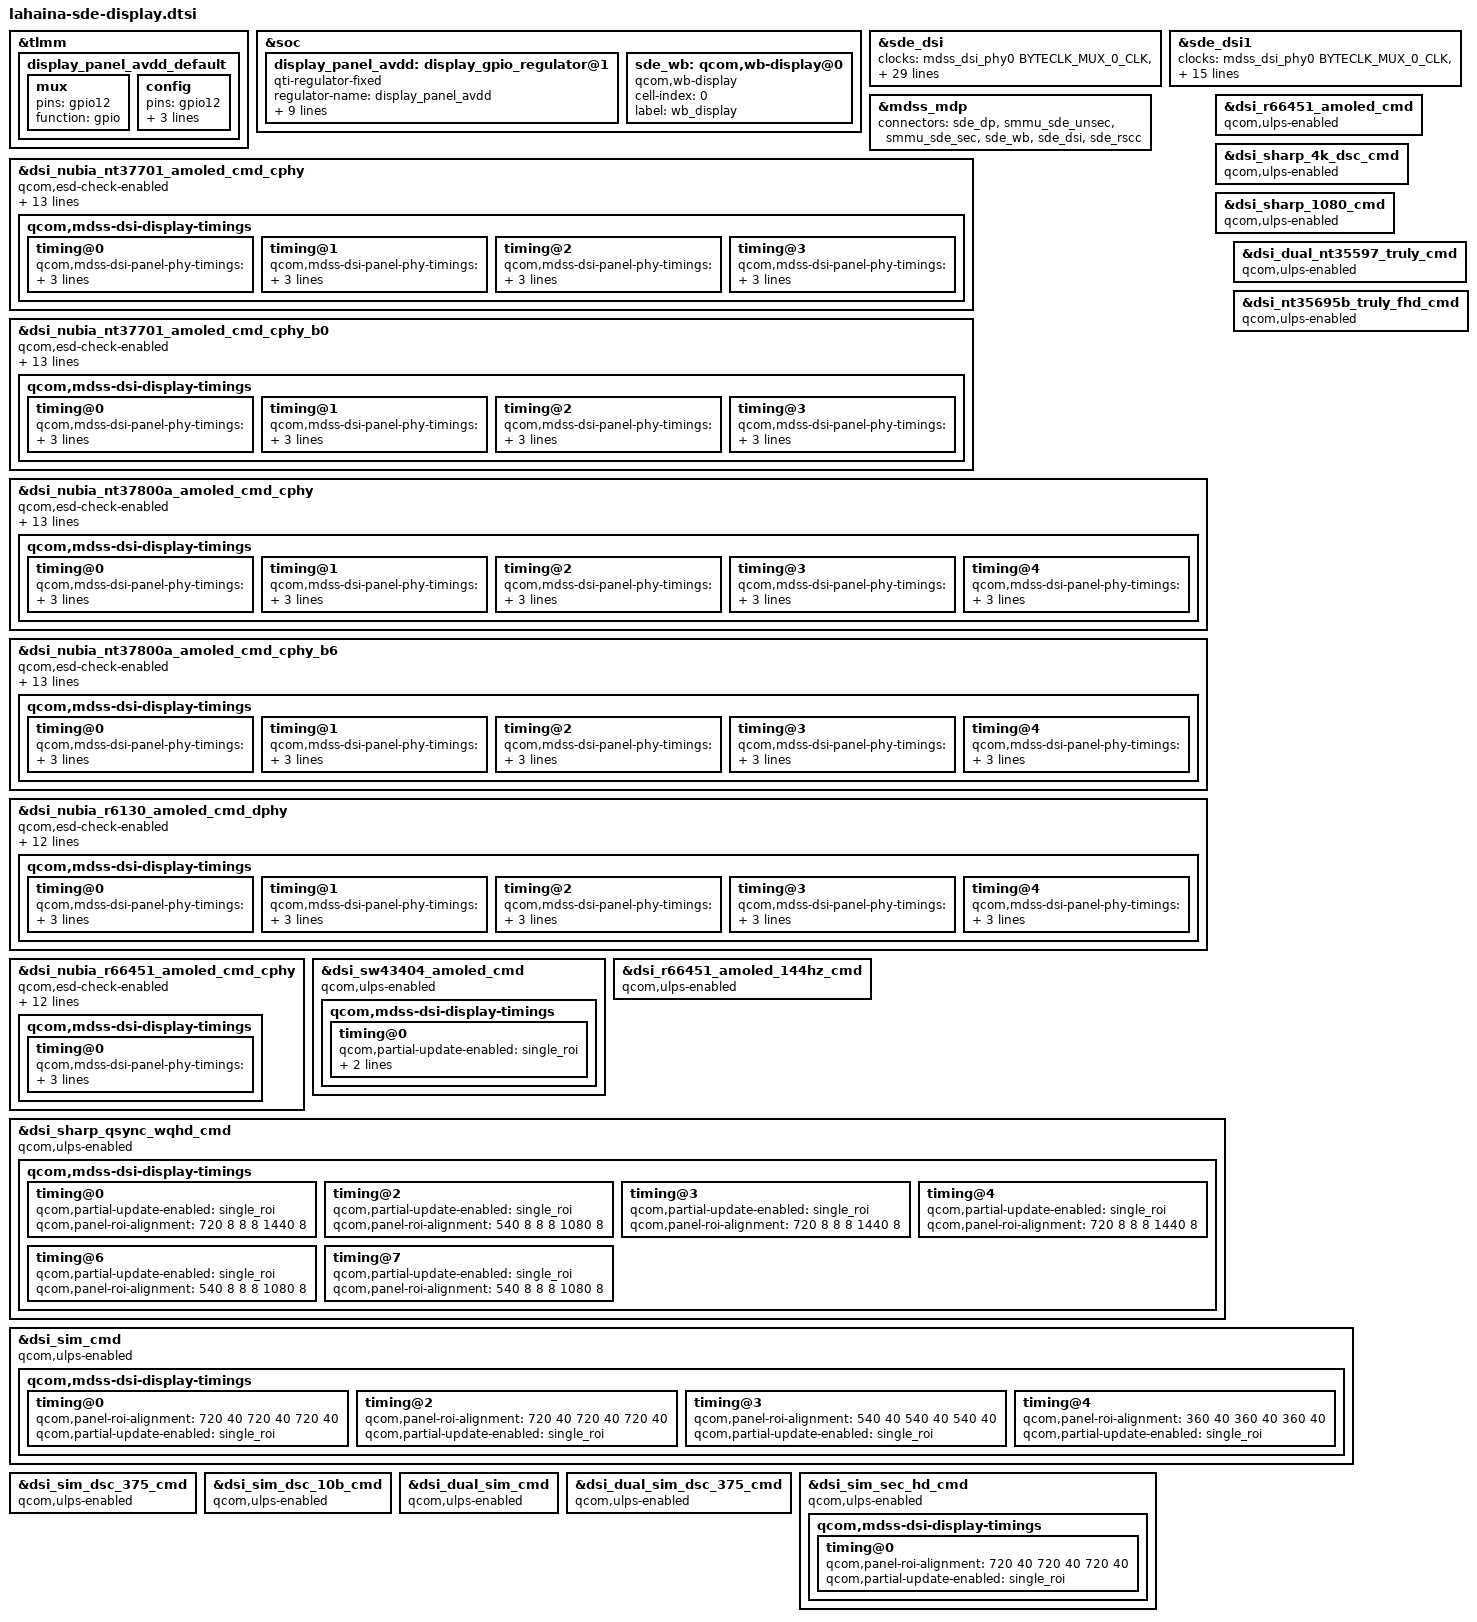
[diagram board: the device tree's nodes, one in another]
#include "lahaina-sde-display-common.dtsi"
#include <dt-bindings/clock/qcom,dispcc-lahaina.h>

&tlmm {
	display_panel_avdd_default: display_panel_avdd_default {
		mux {
			pins = "gpio12";
			function = "gpio";
		};

		config {
			pins = "gpio12";
			drive-strength = <8>;
			bias-disable = <0>;
			output-high;
		};
	};
};

&soc {
	display_panel_avdd: display_gpio_regulator@1 {
		compatible = "qti-regulator-fixed";
		regulator-name = "display_panel_avdd";
		regulator-min-microvolt = <5500000>;
		regulator-max-microvolt = <5500000>;
		regulator-enable-ramp-delay = <233>;
		gpio = <&tlmm 12 0>;
		enable-active-high;
		regulator-boot-on;
		proxy-supply = <&display_panel_avdd>;
		qcom,proxy-consumer-enable;
		pinctrl-names = "default";
		pinctrl-0 = <&display_panel_avdd_default>;
	};

	sde_wb: qcom,wb-display@0 {
		compatible = "qcom,wb-display";
		cell-index = <0>;
		label = "wb_display";
	};
};

&sde_dsi {
	clocks = <&mdss_dsi_phy0 BYTECLK_MUX_0_CLK>,
			 <&mdss_dsi_phy0 PCLK_MUX_0_CLK>,
			 <&mdss_dsi_phy0 CPHY_BYTECLK_SRC_0_CLK>,
			 <&mdss_dsi_phy0 CPHY_PCLK_SRC_0_CLK>,
			 <&mdss_dsi_phy0 BYTECLK_SRC_0_CLK>,
			 <&mdss_dsi_phy0 PCLK_SRC_0_CLK>,
			 <&mdss_dsi_phy0 SHADOW_BYTECLK_SRC_0_CLK>,
			 <&mdss_dsi_phy0 SHADOW_PCLK_SRC_0_CLK>,
			 <&mdss_dsi_phy0 SHADOW_CPHY_BYTECLK_SRC_0_CLK>,
			 <&mdss_dsi_phy0 SHADOW_CPHY_PCLK_SRC_0_CLK>,
			 <&mdss_dsi_phy1 BYTECLK_MUX_1_CLK>,
			 <&mdss_dsi_phy1 PCLK_MUX_1_CLK>,
			 <&mdss_dsi_phy1 CPHY_BYTECLK_SRC_1_CLK>,
			 <&mdss_dsi_phy1 CPHY_PCLK_SRC_1_CLK>,
			 <&mdss_dsi_phy1 BYTECLK_SRC_1_CLK>,
			 <&mdss_dsi_phy1 PCLK_SRC_1_CLK>,
			 <&mdss_dsi_phy1 SHADOW_BYTECLK_SRC_1_CLK>,
			 <&mdss_dsi_phy1 SHADOW_PCLK_SRC_1_CLK>,
			 <&mdss_dsi_phy1 SHADOW_CPHY_BYTECLK_SRC_1_CLK>,
			 <&mdss_dsi_phy1 SHADOW_CPHY_PCLK_SRC_1_CLK>,
			 /*
			  * Currently the dsi clock handles are under the dsi
			  * controller DT node. As soon as the controller probe
			  * finishes, the dispcc sync state can get called before
			  * the dsi_display probe potentially disturbing the clock
			  * votes for cont_splash use case. Hence we are no longer
			  * protected by the component model in this case against the
			  * disp cc sync state getting triggered after the dsi_ctrl
			  * probe. To protect against this incorrect sync state trigger
			  * add this dummy MDP clk vote handle to the dsi_display
			  * DT node. Since the dsi_display driver does not parse
			  * MDP clock nodes, no actual vote shall be added and this
			  * change is done just to satisfy sync state requirements.
			  */
			 <&clock_dispcc DISP_CC_MDSS_MDP_CLK>;
	clock-names = "mux_byte_clk0", "mux_pixel_clk0",
			"cphy_byte_clk0", "cphy_pixel_clk0",
			"src_byte_clk0", "src_pixel_clk0",
			"shadow_byte_clk0", "shadow_pixel_clk0",
			"shadow_cphybyte_clk0", "shadow_cphypixel_clk0",
			"mux_byte_clk1", "mux_pixel_clk1",
			"cphy_byte_clk1", "cphy_pixel_clk1",
			"src_byte_clk1", "src_pixel_clk1",
			"shadow_byte_clk1", "shadow_pixel_clk1",
			"shadow_cphybyte_clk1", "shadow_cphypixel_clk1",
			"mdp_core_clk";

	pinctrl-names = "panel_active", "panel_suspend";
	pinctrl-0 = <&sde_dsi_active &sde_te_active>;
	pinctrl-1 = <&sde_dsi_suspend &sde_te_suspend>;

	qcom,platform-te-gpio = <&tlmm 82 0>;
	qcom,panel-te-source = <0>;

	vddio-supply = <&L12C>;
	vdd-supply = <&L13C>;
	avdd-supply = <&display_panel_avdd>;
	lab-supply = <&ab_vreg>;
	ibb-supply = <&ibb_vreg>;
};

&sde_dsi1 {
	clocks = <&mdss_dsi_phy0 BYTECLK_MUX_0_CLK>,
		 <&mdss_dsi_phy0 PCLK_MUX_0_CLK>,
		 <&mdss_dsi_phy0 CPHY_BYTECLK_SRC_0_CLK>,
		 <&mdss_dsi_phy0 CPHY_PCLK_SRC_0_CLK>,
		 <&mdss_dsi_phy1 BYTECLK_MUX_1_CLK>,
		 <&mdss_dsi_phy1 PCLK_MUX_1_CLK>,
		 <&mdss_dsi_phy1 CPHY_BYTECLK_SRC_1_CLK>,
		 <&mdss_dsi_phy1 CPHY_PCLK_SRC_1_CLK>,
		 /*
		  * Currently the dsi clock handles are under the dsi
		  * controller DT node. As soon as the controller probe
		  * finishes, the dispcc sync state can get called before
		  * the dsi_display probe potentially disturbing the clock
		  * votes for cont_splash use case. Hence we are no longer
		  * protected by the component model in this case against the
		  * disp cc sync state getting triggered after the dsi_ctrl
		  * probe. To protect against this incorrect sync state trigger
		  * add this dummy MDP clk vote handle to the dsi_display
		  * DT node. Since the dsi_display driver does not parse
		  * MDP clock nodes, no actual vote shall be added and this
		  * change is done just to satisfy sync state requirements.
		  */
		 <&clock_dispcc DISP_CC_MDSS_MDP_CLK>;
	clock-names = "mux_byte_clk0", "mux_pixel_clk0",
			"cphy_byte_clk0", "cphy_pixel_clk0",
			"mux_byte_clk1", "mux_pixel_clk1",
			"cphy_byte_clk1", "cphy_pixel_clk1",
			"mdp_core_clk";

	pinctrl-names = "panel_active", "panel_suspend";
	pinctrl-0 = <&sde_dsi1_active &sde_te1_active>;
	pinctrl-1 = <&sde_dsi1_suspend &sde_te1_suspend>;

	qcom,platform-te-gpio = <&tlmm 83 0>;
	qcom,panel-te-source = <1>;

	vddio-supply = <&L12C>;
	vdd-supply = <&L13C>;
	avdd-supply = <&display_panel_avdd>;
};

&mdss_mdp {
	connectors = <&sde_dp &smmu_sde_unsec &smmu_sde_sec &sde_wb &sde_dsi &sde_rscc>;
};

&dsi_nubia_nt37701_amoled_cmd_cphy {
	qcom,esd-check-enabled;
	qcom,mdss-dsi-panel-status-check-mode = "reg_read";
	qcom,mdss-dsi-panel-status-command = [
		06 01 00 01 05 00 01 0D
		06 01 00 01 05 00 01 54
		06 01 00 01 05 00 01 0A
		06 01 00 01 05 00 01 91
		06 01 00 01 05 00 01 03
		06 01 00 01 05 00 01 FA];
	qcom,mdss-dsi-panel-status-command-state = "dsi_lp_mode";
	qcom,mdss-dsi-panel-status-value = <0x00 0x20 0x9c
		0xab 0x2a 0x00 0x14 0xc2 0x00 0x02 0xb0 0x03 0x2a 0x00 0x15 0x05 0x0e 0x03 0x1d 0x0c 0xf0
		0x01 0x00 0x00 0x01  0x00 0x00 0x00 0x00  0x00 0x04 0x00 0x00 0x0e 0x00 0x00 0x00>;
	qcom,mdss-dsi-panel-status-read-length = <1 1 1 18 1 15>;
	qcom,dsi-select-clocks = "mux_byte_clk0", "mux_pixel_clk0",
			"cphy_byte_clk0", "cphy_pixel_clk0";
	qcom,mdss-dsi-display-timings {
		timing@0 { /* 90Hz */
			qcom,mdss-dsi-panel-phy-timings = [00 00 00 00 1F 19
				04 19 04 02 04 00 00 00];
			qcom,display-topology = <1 1 1>;
			qcom,default-topology-index = <0>;
		};
		timing@1 { /* 60Hz */
			qcom,mdss-dsi-panel-phy-timings = [00 00 00 00 1E 14
				03 19 03 02 04 00 00 00];
			qcom,display-topology = <1 1 1>;
			qcom,default-topology-index = <0>;
		};
		timing@2 { /* 120Hz */
			qcom,mdss-dsi-panel-phy-timings = [00 00 00 00 21 1D
				06 19 07 02 04 00 00 00];
			qcom,display-topology = <1 1 1>;
			qcom,default-topology-index = <0>;
		};
		timing@3 { /* 144Hz */
			qcom,mdss-dsi-panel-phy-timings = [00 00 00 00 22 21
				07 19 07 02 04 00 00 00];
			qcom,display-topology = <1 1 1>;
			qcom,default-topology-index = <0>;
		};
	};
};

&dsi_nubia_nt37701_amoled_cmd_cphy_b0 {
	qcom,esd-check-enabled;
	qcom,mdss-dsi-panel-status-check-mode = "reg_read";
	qcom,mdss-dsi-panel-status-command = [
		06 01 00 01 05 00 01 0D
		06 01 00 01 05 00 01 54
		06 01 00 01 05 00 01 0A
		06 01 00 01 05 00 01 91
		06 01 00 01 05 00 01 03
		06 01 00 01 05 00 01 FA];
	qcom,mdss-dsi-panel-status-command-state = "dsi_lp_mode";
	qcom,mdss-dsi-panel-status-value = <0x00 0x20 0x9c
		0xab 0x2a 0x00 0x14 0xc2 0x00 0x02 0xb0 0x03 0x2a 0x00 0x15 0x05 0x0e 0x03 0x1d 0x0c 0xf0
		0x01 0x00 0x00 0x01  0x00 0x00 0x00 0x00  0x00 0x04 0x00 0x00 0x0e 0x00 0x00 0x00>;
	qcom,mdss-dsi-panel-status-read-length = <1 1 1 18 1 15>;
	qcom,dsi-select-clocks = "mux_byte_clk0", "mux_pixel_clk0",
			"cphy_byte_clk0", "cphy_pixel_clk0";
	qcom,mdss-dsi-display-timings {
		timing@0 { /* 90Hz */
			qcom,mdss-dsi-panel-phy-timings = [00 00 00 00 1F 19
				04 19 04 02 04 00 00 00];
			qcom,display-topology = <1 1 1>;
			qcom,default-topology-index = <0>;
		};
		timing@1 { /* 60Hz */
			qcom,mdss-dsi-panel-phy-timings = [00 00 00 00 1E 14
				03 19 03 02 04 00 00 00];
			qcom,display-topology = <1 1 1>;
			qcom,default-topology-index = <0>;
		};
		timing@2 { /* 120Hz */
			qcom,mdss-dsi-panel-phy-timings = [00 00 00 00 21 1D
				06 19 07 02 04 00 00 00];
			qcom,display-topology = <1 1 1>;
			qcom,default-topology-index = <0>;
		};
		timing@3 { /* 144Hz */
			qcom,mdss-dsi-panel-phy-timings = [00 00 00 00 22 21
				07 19 07 02 04 00 00 00];
			qcom,display-topology = <1 1 1>;
			qcom,default-topology-index = <0>;
		};
	};
};

&dsi_nubia_nt37800a_amoled_cmd_cphy {
	qcom,esd-check-enabled;
	qcom,mdss-dsi-panel-status-check-mode = "reg_read";
	qcom,mdss-dsi-panel-status-command = [
		06 01 00 01 05 00 01 0D
		06 01 00 01 05 00 01 54
		06 01 00 01 05 00 01 0A
		06 01 00 01 05 00 01 91
		06 01 00 01 05 00 01 03];
	qcom,mdss-dsi-panel-status-command-state = "dsi_lp_mode";
	qcom,mdss-dsi-panel-status-value = <0x00 0x20 0x9c
		0xAB 0x2A 0x00 0x28 0xC2 0x00 0x01 0xD8 0x04 0xA3 0x00 0x0A 0x02 0x77 0x03 0x1D 0x0C 0xF0
		0x01>;
	qcom,mdss-dsi-panel-status-read-length = <1 1 1 18 1>;
	qcom,dsi-select-clocks = "mux_byte_clk0", "mux_pixel_clk0",
			"cphy_byte_clk0", "cphy_pixel_clk0";
	qcom,mdss-dsi-display-timings {
		timing@0 { /* 90Hz */
			qcom,mdss-dsi-panel-phy-timings = [00 00 00 00 1F 19
				04 19 04 02 04 00 00 00];
			qcom,display-topology = <2 2 1>;
			qcom,default-topology-index = <0>;
		};
		timing@1 { /* 60Hz */
			qcom,mdss-dsi-panel-phy-timings = [00 00 00 00 1E 14
				03 19 03 02 04 00 00 00];
			qcom,display-topology = <2 2 1>;
			qcom,default-topology-index = <0>;
		};
		timing@2 { /* 120Hz */
			qcom,mdss-dsi-panel-phy-timings = [00 00 00 00 21 1D
				06 19 07 02 04 00 00 00];
			qcom,display-topology = <2 2 1>;
			qcom,default-topology-index = <0>;
		};
		timing@3 { /* 144Hz */
			qcom,mdss-dsi-panel-phy-timings = [00 00 00 00 22 21
				07 19 07 02 04 00 00 00];
			qcom,display-topology = <2 2 1>;
			qcom,default-topology-index = <0>;
		};
		timing@4 { /* 165Hz */
			qcom,mdss-dsi-panel-phy-timings = [00 00 00 00 22 21
				07 19 07 02 04 00 00 00];
			qcom,display-topology = <2 2 1>;
			qcom,default-topology-index = <0>;
		};
	};
};

&dsi_nubia_nt37800a_amoled_cmd_cphy_b6 {
	qcom,esd-check-enabled;
	qcom,mdss-dsi-panel-status-check-mode = "reg_read";
	qcom,mdss-dsi-panel-status-command = [
		06 01 00 01 05 00 01 0D
		06 01 00 01 05 00 01 54
		06 01 00 01 05 00 01 0A
		06 01 00 01 05 00 01 91
		06 01 00 01 05 00 01 03];
	qcom,mdss-dsi-panel-status-command-state = "dsi_lp_mode";
	qcom,mdss-dsi-panel-status-value = <0x00 0x20 0x9c
		0xAB 0x2A 0x00 0x28 0xC2 0x00 0x01 0xD8 0x04 0xA3 0x00 0x0A 0x02 0x77 0x03 0x1D 0x0C 0xF0
		0x01>;
	qcom,mdss-dsi-panel-status-read-length = <1 1 1 18 1>;
	qcom,dsi-select-clocks = "mux_byte_clk0", "mux_pixel_clk0",
			"cphy_byte_clk0", "cphy_pixel_clk0";
	qcom,mdss-dsi-display-timings {
		timing@0 { /* 90Hz */
			qcom,mdss-dsi-panel-phy-timings = [00 00 00 00 1F 19
				04 19 04 02 04 00 00 00];
			qcom,display-topology = <2 2 1>;
			qcom,default-topology-index = <0>;
		};
		timing@1 { /* 60Hz */
			qcom,mdss-dsi-panel-phy-timings = [00 00 00 00 1E 14
				03 19 03 02 04 00 00 00];
			qcom,display-topology = <2 2 1>;
			qcom,default-topology-index = <0>;
		};
		timing@2 { /* 120Hz */
			qcom,mdss-dsi-panel-phy-timings = [00 00 00 00 21 1D
				06 19 07 02 04 00 00 00];
			qcom,display-topology = <2 2 1>;
			qcom,default-topology-index = <0>;
		};
		timing@3 { /* 144Hz */
			qcom,mdss-dsi-panel-phy-timings = [00 00 00 00 22 21
				07 19 07 02 04 00 00 00];
			qcom,display-topology = <2 2 1>;
			qcom,default-topology-index = <0>;
		};
		timing@4 { /* 165Hz */
			qcom,mdss-dsi-panel-phy-timings = [00 00 00 00 22 21
				07 19 07 02 04 00 00 00];
			qcom,display-topology = <2 2 1>;
			qcom,default-topology-index = <0>;
		};
	};
};

&dsi_nubia_r6130_amoled_cmd_dphy {
	qcom,esd-check-enabled;
	qcom,mdss-dsi-panel-status-check-mode = "reg_read";
	qcom,mdss-dsi-panel-status-command = [
		06 01 00 01 05 00 01 68
		06 01 00 01 05 00 01 0A];
	qcom,mdss-dsi-panel-status-command-state = "dsi_lp_mode";
	qcom,mdss-dsi-panel-status-value = <0x00 0x00 0x9c>;
	qcom,mdss-dsi-panel-status-read-length = <2 1>;
	qcom,dsi-select-clocks = "mux_byte_clk0", "mux_pixel_clk0",
			"cphy_byte_clk0", "cphy_pixel_clk0";
	qcom,mdss-dsi-display-timings {
		timing@0 { /* 90Hz */
			qcom,mdss-dsi-panel-phy-timings = [00 11 04 04 12 1E
				04 04 03 02 04 00 0F 09];
			qcom,display-topology = <2 2 1>;
			qcom,default-topology-index = <0>;
		};
		timing@1 { /* 60Hz */
			qcom,mdss-dsi-panel-phy-timings = [00 0C 03 03 10 1D
				03 03 02 02 04 00 0B 08];
			qcom,display-topology = <2 2 1>;
			qcom,default-topology-index = <0>;
		};
		timing@2 { /* 120Hz */
			qcom,mdss-dsi-panel-phy-timings = [00 15 05 05 14 13
				05 05 06 02 04 00 13 0A];
			qcom,display-topology = <2 2 1>;
			qcom,default-topology-index = <0>;
		};
		timing@3 { /* 144Hz */
			qcom,mdss-dsi-panel-phy-timings = [00 19 06 06 15 14
				06 06 07 02 04 00 16 0B];
			qcom,display-topology = <2 2 1>;
			qcom,default-topology-index = <0>;
		};
		timing@4 { /* 165Hz */
			qcom,mdss-dsi-panel-phy-timings = [00 1B 07 06 16 15
				07 07 07 02 04 00 17 0B];
			qcom,display-topology = <2 2 1>;
			qcom,default-topology-index = <0>;
		};
	};
};

&dsi_nubia_r66451_amoled_cmd_cphy {
	//qcom,panel-supply-entries = <&dsi_panel_pwr_supply>;
	qcom,esd-check-enabled;
	qcom,mdss-dsi-panel-status-check-mode = "reg_read";
	qcom,mdss-dsi-panel-status-command = [06 01 00 01 05 00 01 0a
		06 01 00 01 05 00 01 f9
		06 01 00 01 05 00 01 f8];
	qcom,mdss-dsi-panel-status-command-state = "dsi_hs_mode";
	qcom,mdss-dsi-panel-status-value = <0x1c 0x00 0x11 0x00 0x00 0x89 0x30 0x80 0x09 0x24 0x04 0x38>;
        qcom,mdss-dsi-panel-status-read-length = <1 1 10>;
	//qcom,dsi-supported-dfps-list = <60 55 48>;
	//qcom,mdss-dsi-pan-enable-dynamic-fps;
	//qcom,mdss-dsi-pan-fps-update = "dfps_immediate_porch_mode_vfp";
	//qcom,mdss-dsi-min-refresh-rate = <48>;
	//qcom,mdss-dsi-max-refresh-rate = <60>;
	qcom,dsi-select-clocks = "mux_byte_clk0", "mux_pixel_clk0",
			"cphy_byte_clk0", "cphy_pixel_clk0";
	qcom,mdss-dsi-display-timings {
		timing@0 { /* 90Hz */
			qcom,mdss-dsi-panel-phy-timings = [00 00 00 00 1E 17
				03 19 03 02 04 00 00 00];
			qcom,display-topology = <1 1 1>;
			qcom,default-topology-index = <0>;
		};
	};
};

&dsi_sw43404_amoled_cmd {
	qcom,ulps-enabled;
	qcom,mdss-dsi-display-timings {
		timing@0 {
			qcom,partial-update-enabled = "single_roi";
			qcom,panel-roi-alignment = <720 180 180 180 1440 180>;
		};
	};
};

&dsi_r66451_amoled_cmd {
	qcom,ulps-enabled;
};

&dsi_r66451_amoled_144hz_cmd {
	qcom,ulps-enabled;
};

&dsi_sharp_4k_dsc_cmd {
	qcom,ulps-enabled;
};

&dsi_sharp_1080_cmd {
	qcom,ulps-enabled;
};

&dsi_sharp_qsync_wqhd_cmd {
	qcom,ulps-enabled;
	qcom,mdss-dsi-display-timings {
		timing@0 { /* WQHD 60FPS CMD */
			qcom,partial-update-enabled = "single_roi";
			qcom,panel-roi-alignment = <720 8 8 8 1440 8>;
		};
		timing@2 { /* FHD 60FPS CMD */
			qcom,partial-update-enabled = "single_roi";
			qcom,panel-roi-alignment = <540 8 8 8 1080 8>;
		};
		timing@3 { /* WQHD 90FPS CMD */
			qcom,partial-update-enabled = "single_roi";
			qcom,panel-roi-alignment = <720 8 8 8 1440 8>;
		};
		timing@4 { /* WQHD 120FPS CMD */
			qcom,partial-update-enabled = "single_roi";
			qcom,panel-roi-alignment = <720 8 8 8 1440 8>;
		};
		timing@6 { /* FHD 120FPS CMD */
			qcom,partial-update-enabled = "single_roi";
			qcom,panel-roi-alignment = <540 8 8 8 1080 8>;
		};
		timing@7 { /* FHD 90FPS CMD */
			qcom,partial-update-enabled = "single_roi";
			qcom,panel-roi-alignment = <540 8 8 8 1080 8>;
		};
	};
};

&dsi_dual_nt35597_truly_cmd {
	qcom,ulps-enabled;
};

&dsi_nt35695b_truly_fhd_cmd {
	qcom,ulps-enabled;
};

&dsi_sim_cmd {
	qcom,ulps-enabled;
	qcom,mdss-dsi-display-timings {
		timing@0 { /* WQHD 60FPS cmd mode*/
			qcom,panel-roi-alignment = <720 40 720 40 720 40>;
			qcom,partial-update-enabled = "single_roi";
		};
		timing@2 { /* WQHD 60FPS cmd mode*/
			qcom,panel-roi-alignment = <720 40 720 40 720 40>;
			qcom,partial-update-enabled = "single_roi";
		};
		timing@3 { /* FHD 60FPS cmd mode*/
			qcom,panel-roi-alignment = <540 40 540 40 540 40>;
			qcom,partial-update-enabled = "single_roi";
		};
		timing@4 { /* HD 60FPS cmd mode*/
			qcom,panel-roi-alignment = <360 40 360 40 360 40>;
			qcom,partial-update-enabled = "single_roi";
		};
	};
};

&dsi_sim_dsc_375_cmd {
	qcom,ulps-enabled;
};

&dsi_sim_dsc_10b_cmd {
	qcom,ulps-enabled;
};

&dsi_dual_sim_cmd {
	qcom,ulps-enabled;
};

&dsi_dual_sim_dsc_375_cmd {
	qcom,ulps-enabled;
};

&dsi_sim_sec_hd_cmd {
	qcom,ulps-enabled;
	qcom,mdss-dsi-display-timings {
		timing@0 {
			qcom,panel-roi-alignment = <720 40 720 40 720 40>;
			qcom,partial-update-enabled = "single_roi";
		};
	};
};
